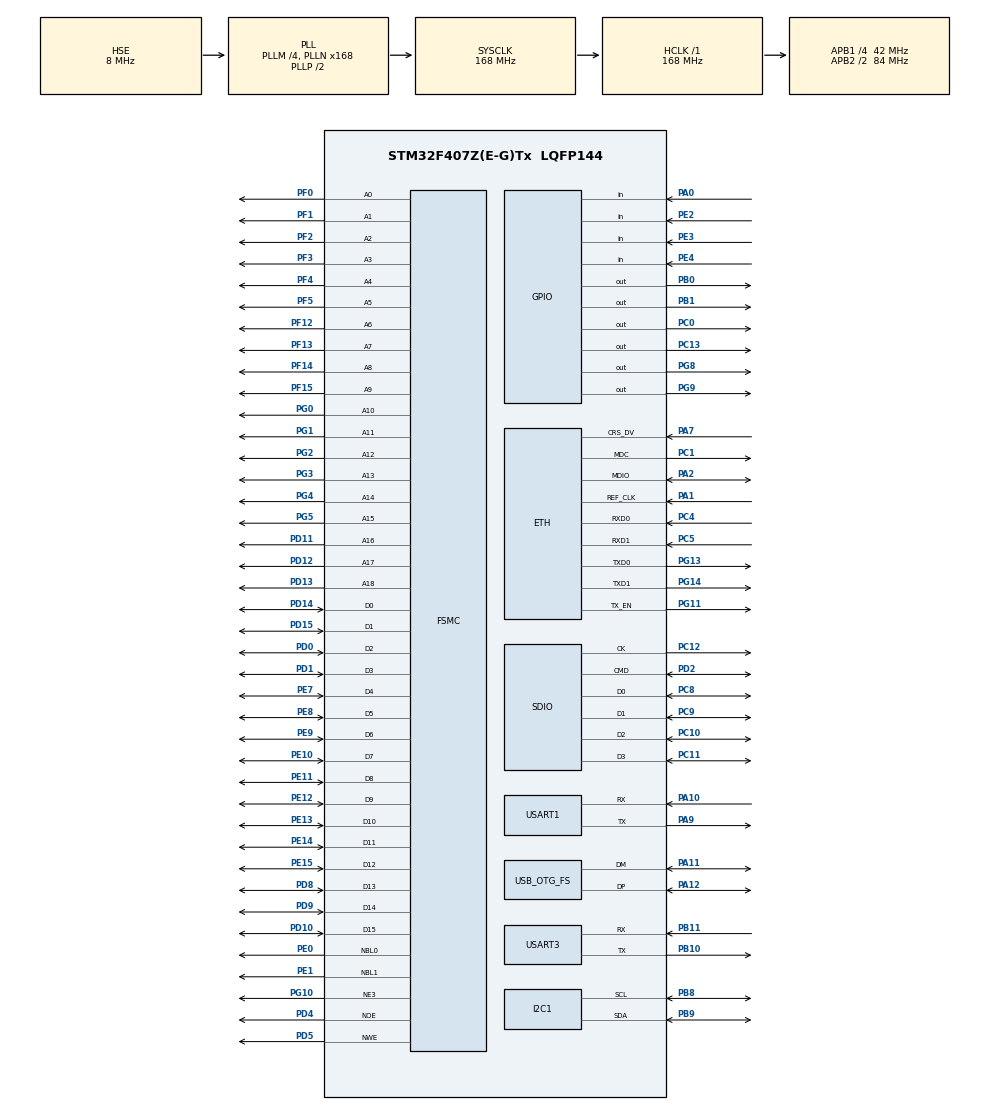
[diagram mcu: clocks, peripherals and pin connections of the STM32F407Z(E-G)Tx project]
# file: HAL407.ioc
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Dma.Request0=USART1_TX
Dma.Request1=SDIO_RX
Dma.Request2=SDIO_TX
Dma.SDIO_RX.1.Direction=DMA_PERIPH_TO_MEMORY
Dma.SDIO_RX.1.FIFOMode=DMA_FIFOMODE_ENABLE
Dma.SDIO_RX.1.FIFOThreshold=DMA_FIFO_THRESHOLD_FULL
Dma.SDIO_RX.1.Instance=DMA2_Stream3
Dma.SDIO_RX.1.MemBurst=DMA_MBURST_INC4
Dma.SDIO_RX.1.MemDataAlignment=DMA_MDATAALIGN_WORD
Dma.SDIO_RX.1.MemInc=DMA_MINC_ENABLE
Dma.SDIO_RX.1.Mode=DMA_PFCTRL
Dma.SDIO_RX.1.PeriphBurst=DMA_PBURST_INC4
Dma.SDIO_RX.1.PeriphDataAlignment=DMA_PDATAALIGN_WORD
Dma.SDIO_RX.1.PeriphInc=DMA_PINC_DISABLE
Dma.SDIO_RX.1.Priority=DMA_PRIORITY_HIGH
Dma.SDIO_TX.2.Direction=DMA_MEMORY_TO_PERIPH
Dma.SDIO_TX.2.FIFOMode=DMA_FIFOMODE_ENABLE
Dma.SDIO_TX.2.FIFOThreshold=DMA_FIFO_THRESHOLD_FULL
Dma.SDIO_TX.2.Instance=DMA2_Stream6
Dma.SDIO_TX.2.MemBurst=DMA_MBURST_INC4
Dma.SDIO_TX.2.MemDataAlignment=DMA_MDATAALIGN_WORD
Dma.SDIO_TX.2.MemInc=DMA_MINC_ENABLE
Dma.SDIO_TX.2.Mode=DMA_PFCTRL
Dma.SDIO_TX.2.PeriphBurst=DMA_PBURST_INC4
Dma.SDIO_TX.2.PeriphDataAlignment=DMA_PDATAALIGN_WORD
Dma.SDIO_TX.2.PeriphInc=DMA_PINC_DISABLE
Dma.SDIO_TX.2.Priority=DMA_PRIORITY_HIGH
Dma.USART1_TX.0.Direction=DMA_MEMORY_TO_PERIPH
Dma.USART1_TX.0.FIFOMode=DMA_FIFOMODE_DISABLE
Dma.USART1_TX.0.Instance=DMA2_Stream7
Dma.USART1_TX.0.MemDataAlignment=DMA_MDATAALIGN_BYTE
Dma.USART1_TX.0.MemInc=DMA_MINC_ENABLE
Dma.USART1_TX.0.Mode=DMA_NORMAL
Dma.USART1_TX.0.PeriphDataAlignment=DMA_PDATAALIGN_BYTE
Dma.USART1_TX.0.PeriphInc=DMA_PINC_DISABLE
Dma.USART1_TX.0.Priority=DMA_PRIORITY_HIGH
ETH.MediaInterface=ETH_MEDIA_INTERFACE_RMII
FREERTOS.Tasks01=defaultTask,0,512,StartDefaultTask,Default,NULL,Dynamic,NULL,NULL
FSMC.AddressSetupTime1=0
FSMC.BusTurnAroundDuration1=0
FSMC.DataSetupTime1=9
FSMC.WriteOperation1=FSMC_WRITE_OPERATION_ENABLE
LWIP.Version=v2.0.0_Cube
Mcu.Family=STM32F4
Mcu.Name=STM32F407Z(E-G)Tx
Mcu.Package=LQFP144
NVIC.DMA2_Stream3_IRQn=true\:5\:0\:false\:false\:true\:true
NVIC.DMA2_Stream6_IRQn=true\:5\:0\:false\:false\:true\:true
NVIC.DMA2_Stream7_IRQn=true\:5\:0\:false\:false\:true\:true
NVIC.ETH_IRQn=true\:5\:0\:false\:false\:true\:true
NVIC.OTG_FS_IRQn=true\:5\:0\:false\:false\:true\:true
NVIC.PriorityGroup=NVIC_PRIORITYGROUP_4
NVIC.SDIO_IRQn=true\:5\:0\:false\:false\:true\:true
NVIC.TIM8_TRG_COM_TIM14_IRQn=true\:0\:0\:false\:false\:true\:false
NVIC.TimeBase=TIM8_TRG_COM_TIM14_IRQn
NVIC.TimeBaseIP=TIM14
NVIC.USART1_IRQn=true\:5\:0\:false\:false\:true\:true
NVIC.USART3_IRQn=true\:5\:0\:false\:false\:true\:true
PA0-WKUP.Signal=GPIO_Input
PA1.Mode=RMII
PA1.Signal=ETH_REF_CLK
PA10.Mode=Asynchronous
PA10.Signal=USART1_RX
PA11.Mode=Device_Only
PA11.Signal=USB_OTG_FS_DM
PA12.GPIO_PuPd=GPIO_PULLUP
PA12.Mode=Device_Only
PA12.Signal=USB_OTG_FS_DP
PA13.Mode=JTAG_5_pins
PA13.Signal=SYS_JTMS-SWDIO
PA14.Mode=JTAG_5_pins
PA14.Signal=SYS_JTCK-SWCLK
PA15.Mode=JTAG_5_pins
PA15.Signal=SYS_JTDI
PA2.Mode=RMII
PA2.Signal=ETH_MDIO
PA7.Mode=RMII
PA7.Signal=ETH_CRS_DV
PA9.Mode=Asynchronous
PA9.Signal=USART1_TX
PB0.PinState=GPIO_PIN_SET
PB0.Signal=GPIO_Output
PB1.PinState=GPIO_PIN_SET
PB1.Signal=GPIO_Output
PB10.Mode=Asynchronous
PB10.Signal=USART3_TX
PB11.Mode=Asynchronous
PB11.Signal=USART3_RX
PB3.Mode=JTAG_5_pins
PB3.Signal=SYS_JTDO-SWO
PB4.Mode=JTAG_5_pins
PB4.Signal=SYS_JTRST
PB8.Mode=I2C
PB8.Signal=I2C1_SCL
PB9.Mode=I2C
PB9.Signal=I2C1_SDA
PC0.GPIO_ModeDefaultOutputPP=GPIO_MODE_OUTPUT_OD
PC0.GPIO_Speed=GPIO_SPEED_FREQ_HIGH
PC0.PinState=GPIO_PIN_SET
PC0.Signal=GPIO_Output
PC1.Mode=RMII
PC1.Signal=ETH_MDC
PC10.Mode=SD_4_bits_Wide_bus
PC10.Signal=SDIO_D2
PC11.Mode=SD_4_bits_Wide_bus
PC11.Signal=SDIO_D3
PC12.Mode=SD_4_bits_Wide_bus
PC12.Signal=SDIO_CK
PC13-ANTI_TAMP.PinState=GPIO_PIN_SET
PC13-ANTI_TAMP.Signal=GPIO_Output
PC14-OSC32_IN.Mode=LSE-External-Oscillator
PC14-OSC32_IN.Signal=RCC_OSC32_IN
PC15-OSC32_OUT.Mode=LSE-External-Oscillator
PC15-OSC32_OUT.Signal=RCC_OSC32_OUT
PC4.Mode=RMII
PC4.Signal=ETH_RXD0
PC5.Mode=RMII
PC5.Signal=ETH_RXD1
PC8.Mode=SD_4_bits_Wide_bus
PC8.Signal=SDIO_D0
PC9.Mode=SD_4_bits_Wide_bus
PC9.Signal=SDIO_D1
PD0.Signal=FSMC_D2_DA2
PD1.Signal=FSMC_D3_DA3
PD10.Signal=FSMC_D15_DA15
PD11.Signal=FSMC_A16_CLE
PD12.Signal=FSMC_A17_ALE
PD13.Signal=FSMC_A18
PD14.Signal=FSMC_D0_DA0
PD15.Signal=FSMC_D1_DA1
PD2.Mode=SD_4_bits_Wide_bus
PD2.Signal=SDIO_CMD
PD4.Signal=FSMC_NOE
PD5.Signal=FSMC_NWE
PD8.Signal=FSMC_D13_DA13
PD9.Signal=FSMC_D14_DA14
PE0.Signal=FSMC_NBL0
PE1.Signal=FSMC_NBL1
PE10.Signal=FSMC_D7_DA7
PE11.Signal=FSMC_D8_DA8
PE12.Signal=FSMC_D9_DA9
PE13.Signal=FSMC_D10_DA10
PE14.Signal=FSMC_D11_DA11
PE15.Signal=FSMC_D12_DA12
PE2.Signal=GPIO_Input
PE3.Signal=GPIO_Input
PE4.Signal=GPIO_Input
PE7.Signal=FSMC_D4_DA4
PE8.Signal=FSMC_D5_DA5
PE9.Signal=FSMC_D6_DA6
PF0.Signal=FSMC_A0
PF1.Signal=FSMC_A1
PF12.Signal=FSMC_A6
PF13.Signal=FSMC_A7
PF14.Signal=FSMC_A8
PF15.Signal=FSMC_A9
PF2.Signal=FSMC_A2
PF3.Signal=FSMC_A3
PF4.Signal=FSMC_A4
PF5.Signal=FSMC_A5
PG0.Signal=FSMC_A10
PG1.Signal=FSMC_A11
PG10.Mode=NorPsramChipSelect3_1
PG10.Signal=FSMC_NE3
PG11.Mode=RMII
PG11.Signal=ETH_TX_EN
PG13.Mode=RMII
PG13.Signal=ETH_TXD0
PG14.Mode=RMII
PG14.Signal=ETH_TXD1
PG2.Signal=FSMC_A12
PG3.Signal=FSMC_A13
PG4.Signal=FSMC_A14
PG5.Signal=FSMC_A15
PG8.PinState=GPIO_PIN_SET
PG8.Signal=GPIO_Output
PG9.Signal=GPIO_Output
PH0-OSC_IN.Mode=HSE-External-Oscillator
PH0-OSC_IN.Signal=RCC_OSC_IN
PH1-OSC_OUT.Mode=HSE-External-Oscillator
PH1-OSC_OUT.Signal=RCC_OSC_OUT
ProjectManager.HeapSize=0x200
ProjectManager.StackSize=0x400
ProjectManager.TargetToolchain=MDK-ARM V5
RCC.48MHZClocksFreq_Value=48000000
RCC.AHBFreq_Value=168000000
RCC.APB1CLKDivider=RCC_HCLK_DIV4
RCC.APB1Freq_Value=42000000
RCC.APB1TimFreq_Value=84000000
RCC.APB2CLKDivider=RCC_HCLK_DIV2
RCC.APB2Freq_Value=84000000
RCC.APB2TimFreq_Value=168000000
RCC.CortexFreq_Value=168000000
RCC.HCLKFreq_Value=168000000
RCC.HSE_VALUE=8000000
RCC.HSI_VALUE=16000000
RCC.PLLM=4
RCC.PLLN=168
RCC.PLLQ=7
RCC.RCC_RTC_Clock_Source=RCC_RTCCLKSOURCE_LSE
RCC.RCC_RTC_Clock_SourceVirtual=RCC_RTCCLKSOURCE_LSE
RCC.SYSCLKFreq_VALUE=168000000
RCC.SYSCLKSource=RCC_SYSCLKSOURCE_PLLCLK
RCC.VCOOutputFreq_Value=336000000
SH.FSMC_A0.0=FSMC_A0,19b-a1
SH.FSMC_A1.0=FSMC_A1,19b-a1
SH.FSMC_A10.0=FSMC_A10,19b-a1
SH.FSMC_A11.0=FSMC_A11,19b-a1
SH.FSMC_A12.0=FSMC_A12,19b-a1
SH.FSMC_A13.0=FSMC_A13,19b-a1
SH.FSMC_A14.0=FSMC_A14,19b-a1
SH.FSMC_A15.0=FSMC_A15,19b-a1
SH.FSMC_A16_CLE.0=FSMC_A16,19b-a1
SH.FSMC_A17_ALE.0=FSMC_A17,19b-a1
SH.FSMC_A18.0=FSMC_A18,19b-a1
SH.FSMC_A2.0=FSMC_A2,19b-a1
SH.FSMC_A3.0=FSMC_A3,19b-a1
SH.FSMC_A4.0=FSMC_A4,19b-a1
SH.FSMC_A5.0=FSMC_A5,19b-a1
SH.FSMC_A6.0=FSMC_A6,19b-a1
SH.FSMC_A7.0=FSMC_A7,19b-a1
SH.FSMC_A8.0=FSMC_A8,19b-a1
SH.FSMC_A9.0=FSMC_A9,19b-a1
SH.FSMC_D0_DA0.0=FSMC_D0,16b-d1
SH.FSMC_D10_DA10.0=FSMC_D10,16b-d1
SH.FSMC_D11_DA11.0=FSMC_D11,16b-d1
SH.FSMC_D12_DA12.0=FSMC_D12,16b-d1
SH.FSMC_D13_DA13.0=FSMC_D13,16b-d1
SH.FSMC_D14_DA14.0=FSMC_D14,16b-d1
SH.FSMC_D15_DA15.0=FSMC_D15,16b-d1
SH.FSMC_D1_DA1.0=FSMC_D1,16b-d1
SH.FSMC_D2_DA2.0=FSMC_D2,16b-d1
SH.FSMC_D3_DA3.0=FSMC_D3,16b-d1
SH.FSMC_D4_DA4.0=FSMC_D4,16b-d1
SH.FSMC_D5_DA5.0=FSMC_D5,16b-d1
SH.FSMC_D6_DA6.0=FSMC_D6,16b-d1
SH.FSMC_D7_DA7.0=FSMC_D7,16b-d1
SH.FSMC_D8_DA8.0=FSMC_D8,16b-d1
SH.FSMC_D9_DA9.0=FSMC_D9,16b-d1
SH.FSMC_NBL0.0=FSMC_NBL0,2ByteEnable1
SH.FSMC_NBL1.0=FSMC_NBL1,2ByteEnable1
SH.FSMC_NOE.0=FSMC_NOE,Sram1
SH.FSMC_NWE.0=FSMC_NWE,Sram1
USART1.VirtualMode=VM_ASYNC
USART3.VirtualMode=VM_ASYNC
USB_DEVICE.CLASS_NAME_FS=MSC
USB_DEVICE.USBD_SELF_POWERED-MSC_FS=0
USB_DEVICE.VirtualMode-MSC_FS=Msc
USB_DEVICE.VirtualModeFS=Msc_FS
USB_OTG_FS.VirtualMode=Device_Only
USB_OTG_FS.vbus_sensing_enable=DISABLE
VP_FATFS_VS_SDIO.Mode=SDIO
VP_FREERTOS_VS_ENABLE.Mode=Enabled
VP_LWIP_VS_Enabled.Mode=Enabled
VP_RTC_VS_RTC_Activate.Mode=RTC_Enabled
VP_RTC_VS_RTC_Calendar.Mode=RTC_Calendar
VP_SYS_VS_tim14.Mode=TIM14
VP_USB_DEVICE_VS_USB_DEVICE_MSC_FS.Mode=MSC_FS
board=HAL407

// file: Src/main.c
/**
  ******************************************************************************
  * File Name          : main.c
  * Description        : Main program body
  ******************************************************************************
  * This notice applies to any and all portions of this file
  * that are not between comment pairs USER CODE BEGIN and
  * USER CODE END. Other portions of this file, whether
  * inserted by the user or by software development tools
  * are owned by their respective copyright owners.
  *
  * Copyright (c) 2017 STMicroelectronics International N.V.
  * All rights reserved.
  *
  * Redistribution and use in source and binary forms, with or without
  * modification, are permitted, provided that the following conditions are met:
  *
  * 1. Redistribution of source code must retain the above copyright notice,
  *    this list of conditions and the following disclaimer.
  * 2. Redistributions in binary form must reproduce the above copyright notice,
  *    this list of conditions and the following disclaimer in the documentation
  *    and/or other materials provided with the distribution.
  * 3. Neither the name of STMicroelectronics nor the names of other
  *    contributors to this software may be used to endorse or promote products
  *    derived from this software without specific written permission.
  * 4. This software, including modifications and/or derivative works of this
  *    software, must execute solely and exclusively on microcontroller or
  *    microprocessor devices manufactured by or for STMicroelectronics.
  * 5. Redistribution and use of this software other than as permitted under
  *    this license is void and will automatically terminate your rights under
  *    this license.
  *
  * THIS SOFTWARE IS PROVIDED BY STMICROELECTRONICS AND CONTRIBUTORS "AS IS"
  * AND ANY EXPRESS, IMPLIED OR STATUTORY WARRANTIES, INCLUDING, BUT NOT
  * LIMITED TO, THE IMPLIED WARRANTIES OF MERCHANTABILITY, FITNESS FOR A
  * PARTICULAR PURPOSE AND NON-INFRINGEMENT OF THIRD PARTY INTELLECTUAL PROPERTY
  * RIGHTS ARE DISCLAIMED TO THE FULLEST EXTENT PERMITTED BY LAW. IN NO EVENT
  * SHALL STMICROELECTRONICS OR CONTRIBUTORS BE LIABLE FOR ANY DIRECT, INDIRECT,
  * INCIDENTAL, SPECIAL, EXEMPLARY, OR CONSEQUENTIAL DAMAGES (INCLUDING, BUT NOT
  * LIMITED TO, PROCUREMENT OF SUBSTITUTE GOODS OR SERVICES; LOSS OF USE, DATA,
  * OR PROFITS; OR BUSINESS INTERRUPTION) HOWEVER CAUSED AND ON ANY THEORY OF
  * LIABILITY, WHETHER IN CONTRACT, STRICT LIABILITY, OR TORT (INCLUDING
  * NEGLIGENCE OR OTHERWISE) ARISING IN ANY WAY OUT OF THE USE OF THIS SOFTWARE,
  * EVEN IF ADVISED OF THE POSSIBILITY OF SUCH DAMAGE.
  *
  ******************************************************************************
  */
#include "main.h"
#include "stm32f4xx_hal.h"
#include "cmsis_os.h"
#include "fatfs.h"
#include "lwip.h"
#include "usb_device.h"

/* USER CODE BEGIN Includes */
#include "bsp.h"
/* USER CODE END Includes */

I2C_HandleTypeDef hi2c1;

RTC_HandleTypeDef hrtc;

SD_HandleTypeDef hsd;
DMA_HandleTypeDef hdma_sdio_rx;
DMA_HandleTypeDef hdma_sdio_tx;

UART_HandleTypeDef huart1;
UART_HandleTypeDef huart3;
DMA_HandleTypeDef hdma_usart1_tx;

SRAM_HandleTypeDef hsram1;

osThreadId defaultTaskHandle;

/* USER CODE BEGIN PV */
/* Private variables ---------------------------------------------------------*/
HAL_SD_CardInfoTypeDef SDCardInfo;
/* USER CODE END PV */

void SystemClock_Config(void);
static void MX_GPIO_Init(void);
static void MX_DMA_Init(void);
static void MX_I2C1_Init(void);
static void MX_RTC_Init(void);
static void MX_SDIO_SD_Init(void);
static void MX_USART1_UART_Init(void);
static void MX_USART3_UART_Init(void);
static void MX_FSMC_Init(void);
void StartDefaultTask(void const * argument);

/* USER CODE BEGIN PFP */
/* Private function prototypes -----------------------------------------------*/

/* USER CODE END PFP */

int main(void)
{

  /* MCU Configuration----------------------------------------------------------*/

  /* Reset of all peripherals, Initializes the Flash interface and the Systick. */
  HAL_Init();

  /* Configure the system clock */
  SystemClock_Config();

  /* Initialize all configured peripherals */
  MX_GPIO_Init();
  MX_DMA_Init();
  MX_I2C1_Init();
  MX_RTC_Init();
  MX_SDIO_SD_Init();
  MX_USART1_UART_Init();
  MX_USART3_UART_Init();
  MX_FSMC_Init();

  /* USER CODE BEGIN 2 */
//bsp_InitUart();
  /* USER CODE END 2 */

  /* Create the thread(s) */
  /* definition and creation of defaultTask */
  osThreadDef(defaultTask, StartDefaultTask, osPriorityNormal, 0, 512);
  defaultTaskHandle = osThreadCreate(osThread(defaultTask), NULL);

  /* Start scheduler */
  osKernelStart();

  /* We should never get here as control is now taken by the scheduler */

  /* Infinite loop */
  while (1)
  {

  }

}

/** System Clock Configuration
*/
void SystemClock_Config(void)
{

  RCC_OscInitTypeDef RCC_OscInitStruct;
  RCC_ClkInitTypeDef RCC_ClkInitStruct;
  RCC_PeriphCLKInitTypeDef PeriphClkInitStruct;

    /**Configure the main internal regulator output voltage
    */
  __HAL_RCC_PWR_CLK_ENABLE();

  __HAL_PWR_VOLTAGESCALING_CONFIG(PWR_REGULATOR_VOLTAGE_SCALE1);

    /**Initializes the CPU, AHB and APB busses clocks
    */
  RCC_OscInitStruct.OscillatorType = RCC_OSCILLATORTYPE_HSE|RCC_OSCILLATORTYPE_LSE;
  RCC_OscInitStruct.HSEState = RCC_HSE_ON;
  RCC_OscInitStruct.LSEState = RCC_LSE_ON;
  RCC_OscInitStruct.PLL.PLLState = RCC_PLL_ON;
  RCC_OscInitStruct.PLL.PLLSource = RCC_PLLSOURCE_HSE;
  RCC_OscInitStruct.PLL.PLLM = 4;
  RCC_OscInitStruct.PLL.PLLN = 168;
  RCC_OscInitStruct.PLL.PLLP = RCC_PLLP_DIV2;
  RCC_OscInitStruct.PLL.PLLQ = 7;
  if (HAL_RCC_OscConfig(&RCC_OscInitStruct) != HAL_OK)
  {
    _Error_Handler(__FILE__, __LINE__);
  }

    /**Initializes the CPU, AHB and APB busses clocks
    */
  RCC_ClkInitStruct.ClockType = RCC_CLOCKTYPE_HCLK|RCC_CLOCKTYPE_SYSCLK
                              |RCC_CLOCKTYPE_PCLK1|RCC_CLOCKTYPE_PCLK2;
  RCC_ClkInitStruct.SYSCLKSource = RCC_SYSCLKSOURCE_PLLCLK;
  RCC_ClkInitStruct.AHBCLKDivider = RCC_SYSCLK_DIV1;
  RCC_ClkInitStruct.APB1CLKDivider = RCC_HCLK_DIV4;
  RCC_ClkInitStruct.APB2CLKDivider = RCC_HCLK_DIV2;

  if (HAL_RCC_ClockConfig(&RCC_ClkInitStruct, FLASH_LATENCY_5) != HAL_OK)
  {
    _Error_Handler(__FILE__, __LINE__);
  }

  PeriphClkInitStruct.PeriphClockSelection = RCC_PERIPHCLK_RTC;
  PeriphClkInitStruct.RTCClockSelection = RCC_RTCCLKSOURCE_LSE;
  if (HAL_RCCEx_PeriphCLKConfig(&PeriphClkInitStruct) != HAL_OK)
  {
    _Error_Handler(__FILE__, __LINE__);
  }

    /**Configure the Systick interrupt time
    */
  HAL_SYSTICK_Config(HAL_RCC_GetHCLKFreq()/1000);

    /**Configure the Systick
    */
  HAL_SYSTICK_CLKSourceConfig(SYSTICK_CLKSOURCE_HCLK);

  /* SysTick_IRQn interrupt configuration */
  HAL_NVIC_SetPriority(SysTick_IRQn, 15, 0);
}

/* I2C1 init function */
static void MX_I2C1_Init(void)
{

  hi2c1.Instance = I2C1;
  hi2c1.Init.ClockSpeed = 100000;
  hi2c1.Init.DutyCycle = I2C_DUTYCYCLE_2;
  hi2c1.Init.OwnAddress1 = 0;
  hi2c1.Init.AddressingMode = I2C_ADDRESSINGMODE_7BIT;
  hi2c1.Init.DualAddressMode = I2C_DUALADDRESS_DISABLE;
  hi2c1.Init.OwnAddress2 = 0;
  hi2c1.Init.GeneralCallMode = I2C_GENERALCALL_DISABLE;
  hi2c1.Init.NoStretchMode = I2C_NOSTRETCH_DISABLE;
  if (HAL_I2C_Init(&hi2c1) != HAL_OK)
  {
    _Error_Handler(__FILE__, __LINE__);
  }

}

/* RTC init function */
static void MX_RTC_Init(void)
{

  RTC_TimeTypeDef sTime;
  RTC_DateTypeDef sDate;

    /**Initialize RTC Only
    */
  hrtc.Instance = RTC;
  hrtc.Init.HourFormat = RTC_HOURFORMAT_24;
  hrtc.Init.AsynchPrediv = 127;
  hrtc.Init.SynchPrediv = 255;
  hrtc.Init.OutPut = RTC_OUTPUT_DISABLE;
  hrtc.Init.OutPutPolarity = RTC_OUTPUT_POLARITY_HIGH;
  hrtc.Init.OutPutType = RTC_OUTPUT_TYPE_OPENDRAIN;
  if (HAL_RTC_Init(&hrtc) != HAL_OK)
  {
    _Error_Handler(__FILE__, __LINE__);
  }

    /**Initialize RTC and set the Time and Date
    */
  if(HAL_RTCEx_BKUPRead(&hrtc, RTC_BKP_DR0) != 0x32F2){
  sTime.Hours = 0x0;
  sTime.Minutes = 0x0;
  sTime.Seconds = 0x0;
  sTime.DayLightSaving = RTC_DAYLIGHTSAVING_NONE;
  sTime.StoreOperation = RTC_STOREOPERATION_RESET;
  if (HAL_RTC_SetTime(&hrtc, &sTime, RTC_FORMAT_BCD) != HAL_OK)
  {
    _Error_Handler(__FILE__, __LINE__);
  }

  sDate.WeekDay = RTC_WEEKDAY_MONDAY;
  sDate.Month = RTC_MONTH_JANUARY;
  sDate.Date = 0x1;
  sDate.Year = 0x0;

  if (HAL_RTC_SetDate(&hrtc, &sDate, RTC_FORMAT_BCD) != HAL_OK)
  {
    _Error_Handler(__FILE__, __LINE__);
  }

    HAL_RTCEx_BKUPWrite(&hrtc,RTC_BKP_DR0,0x32F2);
  }

}

/* SDIO init function */
static void MX_SDIO_SD_Init(void)
{

  hsd.Instance = SDIO;
  hsd.Init.ClockEdge = SDIO_CLOCK_EDGE_RISING;
  hsd.Init.ClockBypass = SDIO_CLOCK_BYPASS_DISABLE;
  hsd.Init.ClockPowerSave = SDIO_CLOCK_POWER_SAVE_DISABLE;
  hsd.Init.BusWide = SDIO_BUS_WIDE_1B;
  hsd.Init.HardwareFlowControl = SDIO_HARDWARE_FLOW_CONTROL_DISABLE;
  hsd.Init.ClockDiv = 0;

}

/* USART1 init function */
static void MX_USART1_UART_Init(void)
{

  huart1.Instance = USART1;
  huart1.Init.BaudRate = 115200;
  huart1.Init.WordLength = UART_WORDLENGTH_8B;
  huart1.Init.StopBits = UART_STOPBITS_1;
  huart1.Init.Parity = UART_PARITY_NONE;
  huart1.Init.Mode = UART_MODE_TX_RX;
  huart1.Init.HwFlowCtl = UART_HWCONTROL_NONE;
  huart1.Init.OverSampling = UART_OVERSAMPLING_16;
  if (HAL_UART_Init(&huart1) != HAL_OK)
  {
    _Error_Handler(__FILE__, __LINE__);
  }

}

/* USART3 init function */
static void MX_USART3_UART_Init(void)
{

  huart3.Instance = USART3;
  huart3.Init.BaudRate = 115200;
  huart3.Init.WordLength = UART_WORDLENGTH_8B;
  huart3.Init.StopBits = UART_STOPBITS_1;
  huart3.Init.Parity = UART_PARITY_NONE;
  huart3.Init.Mode = UART_MODE_TX_RX;
  huart3.Init.HwFlowCtl = UART_HWCONTROL_NONE;
  huart3.Init.OverSampling = UART_OVERSAMPLING_16;
  if (HAL_UART_Init(&huart3) != HAL_OK)
  {
    _Error_Handler(__FILE__, __LINE__);
  }

}

static void MX_DMA_Init(void)
{
  /* DMA controller clock enable */
  __HAL_RCC_DMA2_CLK_ENABLE();

  /* DMA interrupt init */
  /* DMA2_Stream3_IRQn interrupt configuration */
  HAL_NVIC_SetPriority(DMA2_Stream3_IRQn, 5, 0);
  HAL_NVIC_EnableIRQ(DMA2_Stream3_IRQn);
  /* DMA2_Stream6_IRQn interrupt configuration */
  HAL_NVIC_SetPriority(DMA2_Stream6_IRQn, 5, 0);
  HAL_NVIC_EnableIRQ(DMA2_Stream6_IRQn);
  /* DMA2_Stream7_IRQn interrupt configuration */
  HAL_NVIC_SetPriority(DMA2_Stream7_IRQn, 5, 0);
  HAL_NVIC_EnableIRQ(DMA2_Stream7_IRQn);

}

/** Configure pins as
        * Analog
        * Input
        * Output
        * EVENT_OUT
        * EXTI
*/
static void MX_GPIO_Init(void)
{

  GPIO_InitTypeDef GPIO_InitStruct;

  /* GPIO Ports Clock Enable */
  __HAL_RCC_GPIOE_CLK_ENABLE();
  __HAL_RCC_GPIOC_CLK_ENABLE();
  __HAL_RCC_GPIOF_CLK_ENABLE();
  __HAL_RCC_GPIOH_CLK_ENABLE();
  __HAL_RCC_GPIOA_CLK_ENABLE();
  __HAL_RCC_GPIOB_CLK_ENABLE();
  __HAL_RCC_GPIOG_CLK_ENABLE();
  __HAL_RCC_GPIOD_CLK_ENABLE();

  /*Configure GPIO pin Output Level */
  HAL_GPIO_WritePin(GPIOC, GPIO_PIN_13|GPIO_PIN_0, GPIO_PIN_SET);

  /*Configure GPIO pin Output Level */
  HAL_GPIO_WritePin(GPIOB, GPIO_PIN_0|GPIO_PIN_1, GPIO_PIN_SET);

  /*Configure GPIO pin Output Level */
  HAL_GPIO_WritePin(GPIOG, GPIO_PIN_8, GPIO_PIN_SET);

  /*Configure GPIO pin Output Level */
  HAL_GPIO_WritePin(GPIOG, GPIO_PIN_9, GPIO_PIN_RESET);

  /*Configure GPIO pins : PE2 PE3 PE4 */
  GPIO_InitStruct.Pin = GPIO_PIN_2|GPIO_PIN_3|GPIO_PIN_4;
  GPIO_InitStruct.Mode = GPIO_MODE_INPUT;
  GPIO_InitStruct.Pull = GPIO_NOPULL;
  HAL_GPIO_Init(GPIOE, &GPIO_InitStruct);

  /*Configure GPIO pin : PC13 */
  GPIO_InitStruct.Pin = GPIO_PIN_13;
  GPIO_InitStruct.Mode = GPIO_MODE_OUTPUT_PP;
  GPIO_InitStruct.Pull = GPIO_NOPULL;
  GPIO_InitStruct.Speed = GPIO_SPEED_FREQ_LOW;
  HAL_GPIO_Init(GPIOC, &GPIO_InitStruct);

  /*Configure GPIO pin : PC0 */
  GPIO_InitStruct.Pin = GPIO_PIN_0;
  GPIO_InitStruct.Mode = GPIO_MODE_OUTPUT_OD;
  GPIO_InitStruct.Pull = GPIO_NOPULL;
  GPIO_InitStruct.Speed = GPIO_SPEED_FREQ_HIGH;
  HAL_GPIO_Init(GPIOC, &GPIO_InitStruct);

  /*Configure GPIO pin : PA0 */
  GPIO_InitStruct.Pin = GPIO_PIN_0;
  GPIO_InitStruct.Mode = GPIO_MODE_INPUT;
  GPIO_InitStruct.Pull = GPIO_NOPULL;
  HAL_GPIO_Init(GPIOA, &GPIO_InitStruct);

  /*Configure GPIO pins : PB0 PB1 */
  GPIO_InitStruct.Pin = GPIO_PIN_0|GPIO_PIN_1;
  GPIO_InitStruct.Mode = GPIO_MODE_OUTPUT_PP;
  GPIO_InitStruct.Pull = GPIO_NOPULL;
  GPIO_InitStruct.Speed = GPIO_SPEED_FREQ_LOW;
  HAL_GPIO_Init(GPIOB, &GPIO_InitStruct);

  /*Configure GPIO pins : PG8 PG9 */
  GPIO_InitStruct.Pin = GPIO_PIN_8|GPIO_PIN_9;
  GPIO_InitStruct.Mode = GPIO_MODE_OUTPUT_PP;
  GPIO_InitStruct.Pull = GPIO_NOPULL;
  GPIO_InitStruct.Speed = GPIO_SPEED_FREQ_LOW;
  HAL_GPIO_Init(GPIOG, &GPIO_InitStruct);

}

/* FSMC initialization function */
static void MX_FSMC_Init(void)
{
  FSMC_NORSRAM_TimingTypeDef Timing;

  /** Perform the SRAM1 memory initialization sequence
  */
  hsram1.Instance = FSMC_NORSRAM_DEVICE;
  hsram1.Extended = FSMC_NORSRAM_EXTENDED_DEVICE;
  /* hsram1.Init */
  hsram1.Init.NSBank = FSMC_NORSRAM_BANK3;
  hsram1.Init.DataAddressMux = FSMC_DATA_ADDRESS_MUX_DISABLE;
  hsram1.Init.MemoryType = FSMC_MEMORY_TYPE_SRAM;
  hsram1.Init.MemoryDataWidth = FSMC_NORSRAM_MEM_BUS_WIDTH_16;
  hsram1.Init.BurstAccessMode = FSMC_BURST_ACCESS_MODE_DISABLE;
  hsram1.Init.WaitSignalPolarity = FSMC_WAIT_SIGNAL_POLARITY_LOW;
  hsram1.Init.WrapMode = FSMC_WRAP_MODE_DISABLE;
  hsram1.Init.WaitSignalActive = FSMC_WAIT_TIMING_BEFORE_WS;
  hsram1.Init.WriteOperation = FSMC_WRITE_OPERATION_ENABLE;
  hsram1.Init.WaitSignal = FSMC_WAIT_SIGNAL_DISABLE;
  hsram1.Init.ExtendedMode = FSMC_EXTENDED_MODE_DISABLE;
  hsram1.Init.AsynchronousWait = FSMC_ASYNCHRONOUS_WAIT_DISABLE;
  hsram1.Init.WriteBurst = FSMC_WRITE_BURST_DISABLE;
  hsram1.Init.PageSize = FSMC_PAGE_SIZE_NONE;
  /* Timing */
  Timing.AddressSetupTime = 0;
  Timing.AddressHoldTime = 15;
  Timing.DataSetupTime = 9;
  Timing.BusTurnAroundDuration = 0;
  Timing.CLKDivision = 16;
  Timing.DataLatency = 17;
  Timing.AccessMode = FSMC_ACCESS_MODE_A;
  /* ExtTiming */

  if (HAL_SRAM_Init(&hsram1, &Timing, NULL) != HAL_OK)
  {
    _Error_Handler(__FILE__, __LINE__);
  }

}

/* StartDefaultTask function */
void StartDefaultTask(void const * argument)
{
  /* init code for FATFS */
  MX_FATFS_Init();

  /* init code for LWIP */
  MX_LWIP_Init();

  /* init code for USB_DEVICE */
  MX_USB_DEVICE_Init();

  /* USER CODE BEGIN 5 */
  HAL_UART_Transmit(&huart1,"Startup\r\n",9,0xffff);
//HAL_UART_Transmit_IT(&huart1,"Startup\r\n",9);
//HAL_UART_Transmit_DMA(&huart1,"Start dma\r\n",10);
  /* Infinite loop */
  for(;;)
  {
//    HAL_UART_Transmit(&huart1,"com1\r\n",6,0xffff);

//
//    osDelay(500);
      Task_Default(argument);
  }
  /* USER CODE END 5 */
}

void HAL_TIM_PeriodElapsedCallback(TIM_HandleTypeDef *htim)
{
  if (htim->Instance == TIM14) {
    HAL_IncTick();
  }
}

void _Error_Handler(char * file, int line)
{
  while(1)
  {
  }
}

/************************ (C) COPYRIGHT STMicroelectronics *****END OF FILE****/
